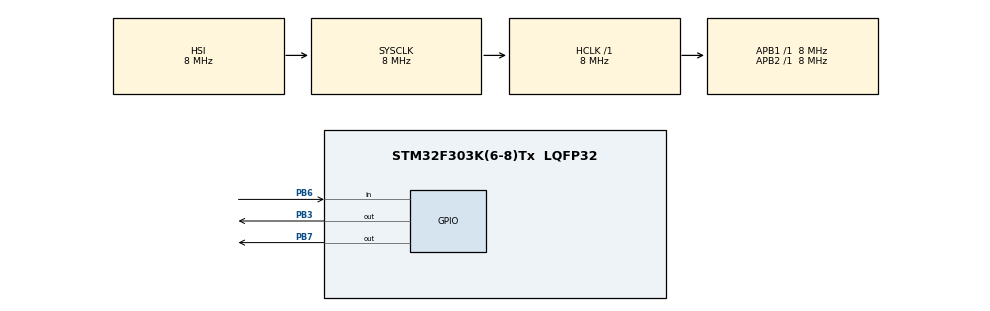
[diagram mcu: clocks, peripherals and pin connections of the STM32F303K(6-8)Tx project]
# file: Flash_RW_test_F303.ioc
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Mcu.Family=STM32F3
Mcu.Name=STM32F303K(6-8)Tx
Mcu.Package=LQFP32
NVIC.PriorityGroup=NVIC_PRIORITYGROUP_4
PB3.PinState=GPIO_PIN_SET
PB3.Signal=GPIO_Output
PB6.GPIO_PuPd=GPIO_PULLUP
PB6.Signal=GPIO_Input
PB7.Signal=GPIO_Output
ProjectManager.HeapSize=0x200
ProjectManager.StackSize=0x400
ProjectManager.TargetToolchain=STM32CubeIDE
RCC.AHBFreq_Value=8000000
RCC.APB1Freq_Value=8000000
RCC.APB2Freq_Value=8000000
RCC.CortexFreq_Value=8000000
RCC.HSE_VALUE=8000000
RCC.HSI_VALUE=8000000
RCC.SYSCLKFreq_VALUE=8000000
board=custom

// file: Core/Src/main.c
/* USER CODE BEGIN Header */
/**
 ******************************************************************************
 * @file           : main.c
 * @brief          : Main program body
 ******************************************************************************
 * @attention
 *
 * Copyright (c) 2024 STMicroelectronics.
 * All rights reserved.
 *
 * This software is licensed under terms that can be found in the LICENSE file
 * in the root directory of this software component.
 * If no LICENSE file comes with this software, it is provided AS-IS.
 *
 ******************************************************************************
 */
/* USER CODE END Header */
#include "main.h"

/* USER CODE BEGIN PV */
uint32_t readValue = 0;
uint32_t flashAddress = 0x08005000; // Example flash address, ensure it is a valid address in your MCU's flash memory
uint8_t mode = 0;
/* USER CODE END PV */

void SystemClock_Config(void);
static void MX_GPIO_Init(void);
/* USER CODE BEGIN PFP */
void Flash_EnableReadProtection(void);
void Flash_DisableReadProtection(void);
HAL_StatusTypeDef WriteUint32ToFlash(uint32_t address, uint32_t value);
uint32_t ReadUint32FromFlash(uint32_t address);
/* USER CODE END PFP */

int main(void) {

	/* USER CODE BEGIN 1 */
//	Flash_EnableReadProtection();
	/* USER CODE END 1 */

	/* MCU Configuration--------------------------------------------------------*/

	/* Reset of all peripherals, Initializes the Flash interface and the Systick. */
	HAL_Init();

	/* Configure the system clock */
	SystemClock_Config();

	/* Initialize all configured peripherals */
	MX_GPIO_Init();
	/* USER CODE BEGIN 2 */
	readValue = ReadUint32FromFlash(flashAddress);

	if (readValue == 0) {
		mode = 0;
	} else if (readValue == 1) {
		mode = 1;
	} else {
		mode = 0;
		WriteUint32ToFlash(flashAddress, 0);
	}

	if (!HAL_GPIO_ReadPin(GPIOB, GPIO_PIN_6)) {
		if (mode == 0) {
			WriteUint32ToFlash(flashAddress, 1);
		} else if (mode == 1) {
			WriteUint32ToFlash(flashAddress, 0);
		}
		while (1) {
		}
	}

	/* USER CODE END 2 */

	/* Infinite loop */
	while (1) {
		HAL_GPIO_TogglePin(GPIOB, GPIO_PIN_3);
		if (mode == 0) {
			HAL_Delay(1000);
		} else if (mode == 1) {
			HAL_Delay(200);
		}
	}
}

void SystemClock_Config(void) {
	RCC_OscInitTypeDef RCC_OscInitStruct = { 0 };
	RCC_ClkInitTypeDef RCC_ClkInitStruct = { 0 };

	/** Initializes the RCC Oscillators according to the specified parameters
	 * in the RCC_OscInitTypeDef structure.
	 */
	RCC_OscInitStruct.OscillatorType = RCC_OSCILLATORTYPE_HSI;
	RCC_OscInitStruct.HSIState = RCC_HSI_ON;
	RCC_OscInitStruct.HSICalibrationValue = RCC_HSICALIBRATION_DEFAULT;
	RCC_OscInitStruct.PLL.PLLState = RCC_PLL_NONE;
	if (HAL_RCC_OscConfig(&RCC_OscInitStruct) != HAL_OK) {
		Error_Handler();
	}

	/** Initializes the CPU, AHB and APB buses clocks
	 */
	RCC_ClkInitStruct.ClockType = RCC_CLOCKTYPE_HCLK | RCC_CLOCKTYPE_SYSCLK
			| RCC_CLOCKTYPE_PCLK1 | RCC_CLOCKTYPE_PCLK2;
	RCC_ClkInitStruct.SYSCLKSource = RCC_SYSCLKSOURCE_HSI;
	RCC_ClkInitStruct.AHBCLKDivider = RCC_SYSCLK_DIV1;
	RCC_ClkInitStruct.APB1CLKDivider = RCC_HCLK_DIV1;
	RCC_ClkInitStruct.APB2CLKDivider = RCC_HCLK_DIV1;

	if (HAL_RCC_ClockConfig(&RCC_ClkInitStruct, FLASH_LATENCY_0) != HAL_OK) {
		Error_Handler();
	}
}

static void MX_GPIO_Init(void) {
	GPIO_InitTypeDef GPIO_InitStruct = { 0 };

	/* GPIO Ports Clock Enable */
	__HAL_RCC_GPIOB_CLK_ENABLE();

	/*Configure GPIO pin Output Level */
	HAL_GPIO_WritePin(GPIOB, GPIO_PIN_3, GPIO_PIN_SET);

	/*Configure GPIO pin Output Level */
	HAL_GPIO_WritePin(GPIOB, GPIO_PIN_7, GPIO_PIN_RESET);

	/*Configure GPIO pins : PB3 PB7 */
	GPIO_InitStruct.Pin = GPIO_PIN_3 | GPIO_PIN_7;
	GPIO_InitStruct.Mode = GPIO_MODE_OUTPUT_PP;
	GPIO_InitStruct.Pull = GPIO_NOPULL;
	GPIO_InitStruct.Speed = GPIO_SPEED_FREQ_LOW;
	HAL_GPIO_Init(GPIOB, &GPIO_InitStruct);

	/*Configure GPIO pin : PB6 */
	GPIO_InitStruct.Pin = GPIO_PIN_6;
	GPIO_InitStruct.Mode = GPIO_MODE_INPUT;
	GPIO_InitStruct.Pull = GPIO_PULLUP;
	HAL_GPIO_Init(GPIOB, &GPIO_InitStruct);

}

/* USER CODE BEGIN 4 */
HAL_StatusTypeDef WriteUint32ToFlash(uint32_t address, uint32_t value) {
	HAL_StatusTypeDef status;

	// Erase the page before writing (optional, ensure the page does not have other useful data)
	FLASH_EraseInitTypeDef eraseInitStruct;

	// Unlock the Flash to enable the flash control register access
	HAL_FLASH_Unlock();

	eraseInitStruct.TypeErase = FLASH_TYPEERASE_PAGES;
	eraseInitStruct.PageAddress = address;
	eraseInitStruct.NbPages = 1;

	uint32_t pageError = 0;
	status = HAL_FLASHEx_Erase(&eraseInitStruct, &pageError);

	if (status != HAL_OK) {
		HAL_FLASH_Lock();
		return status;
	}

	// Program the value
	status = HAL_FLASH_Program(FLASH_TYPEPROGRAM_WORD, address,
			(uint32_t) value);

	// Lock the Flash to disable the flash control register access
	HAL_FLASH_Lock();

	return status;
}

uint32_t ReadUint32FromFlash(uint32_t address) {
	// Read the value directly from the flash memory
	return *(uint32_t*) address;
}

void Flash_EnableReadProtection(void) {

	FLASH_OBProgramInitTypeDef OBInit;

	__HAL_FLASH_PREFETCH_BUFFER_DISABLE();

	HAL_FLASHEx_OBGetConfig(&OBInit);
	if (OBInit.RDPLevel == OB_RDP_LEVEL_0) {
		OBInit.OptionType = OPTIONBYTE_RDP;
		OBInit.RDPLevel = OB_RDP_LEVEL_1;
		HAL_FLASH_Unlock();
		HAL_FLASH_OB_Unlock();
		HAL_FLASHEx_OBProgram(&OBInit);
		HAL_FLASH_OB_Lock();
		HAL_FLASH_Lock();
	}
	__HAL_FLASH_PREFETCH_BUFFER_ENABLE();

}

void Flash_DisableReadProtection(void) {

	FLASH_OBProgramInitTypeDef OBInit;

	__HAL_FLASH_PREFETCH_BUFFER_DISABLE();

	HAL_FLASHEx_OBGetConfig(&OBInit);
	if (OBInit.RDPLevel == OB_RDP_LEVEL_1) {
		OBInit.OptionType = OPTIONBYTE_RDP;
		OBInit.RDPLevel = OB_RDP_LEVEL_0;
		HAL_FLASH_Unlock();
		HAL_FLASH_OB_Unlock();
		HAL_FLASHEx_OBProgram(&OBInit);
		HAL_FLASH_OB_Lock();
		HAL_FLASH_Lock();
	}
	__HAL_FLASH_PREFETCH_BUFFER_ENABLE();
}
/* USER CODE END 4 */

void Error_Handler(void) {
	__disable_irq();
	while (1) {
	}
}
